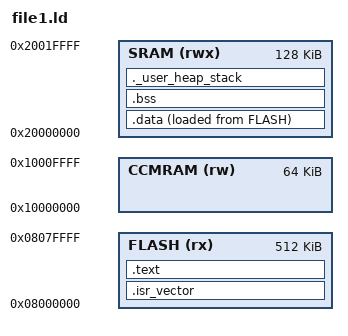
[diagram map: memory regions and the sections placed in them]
/* Linker script for ARM Cortex-M4 embedded firmware */

MEMORY
{
  FLASH (rx)  : ORIGIN = 0x08000000, LENGTH = 512K
  SRAM  (rwx) : ORIGIN = 0x20000000, LENGTH = 128K
  CCMRAM (rw) : ORIGIN = 0x10000000, LENGTH = 64K
}

_stack_size = 0x2000;
_heap_size  = 0x4000;

SECTIONS
{
  .isr_vector :
  {
    . = ALIGN(4);
    KEEP(*(.isr_vector))
    . = ALIGN(4);
  } >FLASH

  .text :
  {
    . = ALIGN(4);
    *(.text)
    *(.text*)
    *(.glue_7)
    *(.glue_7t)
    *(.rodata)
    *(.rodata*)
    KEEP(*(.init))
    KEEP(*(.fini))
    . = ALIGN(4);
    _etext = .;
  } >FLASH

  .data :
  {
    . = ALIGN(4);
    _sdata = .;
    *(.data)
    *(.data*)
    . = ALIGN(4);
    _edata = .;
  } >SRAM AT>FLASH

  .bss :
  {
    . = ALIGN(4);
    _sbss = .;
    *(.bss)
    *(.bss*)
    *(COMMON)
    . = ALIGN(4);
    _ebss = .;
  } >SRAM

  ._user_heap_stack :
  {
    . = ALIGN(8);
    PROVIDE(end = .);
    . = . + _heap_size;
    . = . + _stack_size;
    . = ALIGN(8);
  } >SRAM
}
